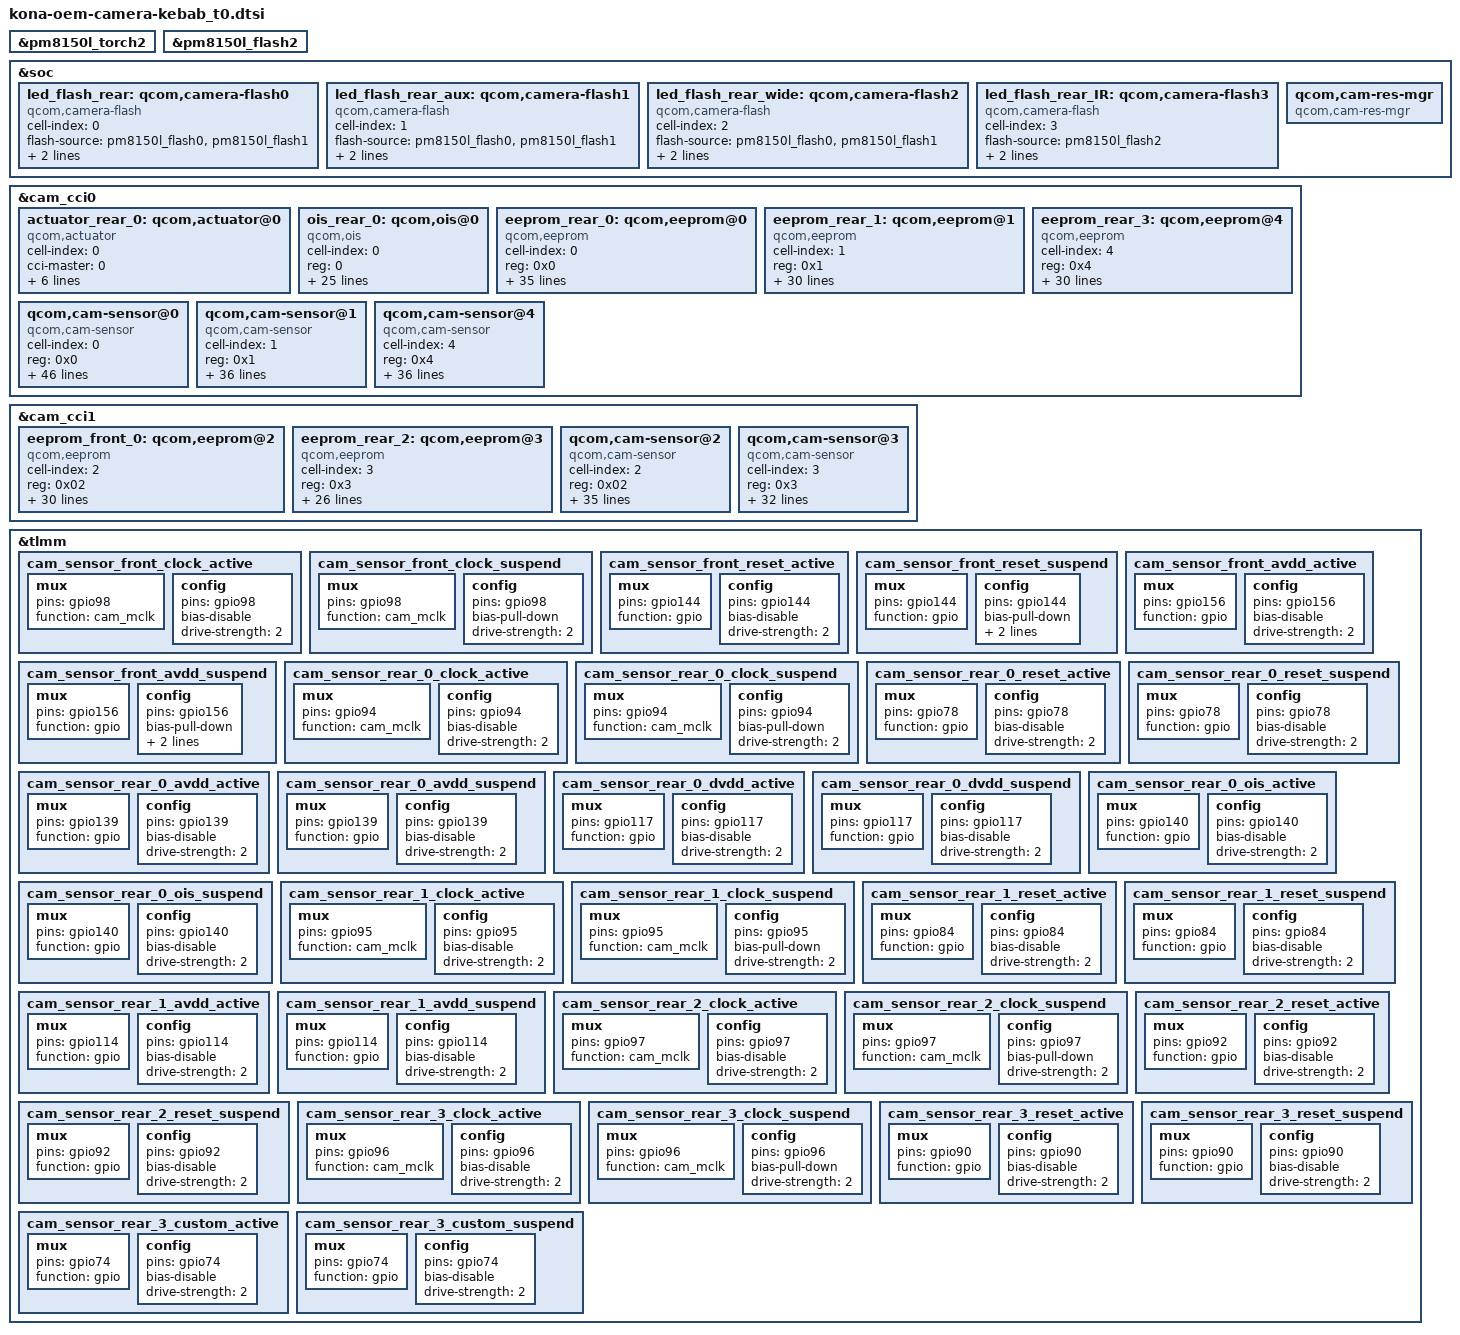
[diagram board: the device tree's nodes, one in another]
&pm8150l_torch2 {
	status = "ok";
};
&pm8150l_flash2 {
	status = "ok";
};

&soc {
    led_flash_rear: qcom,camera-flash0 {
        cell-index = <0>;
        compatible = "qcom,camera-flash";
        flash-source = <&pm8150l_flash0 &pm8150l_flash1>;
        torch-source = <&pm8150l_torch0 &pm8150l_torch1>;
        switch-source = <&pm8150l_switch2>;
        status = "ok";
    };

    led_flash_rear_aux: qcom,camera-flash1 {
        cell-index = <1>;
        compatible = "qcom,camera-flash";
        flash-source = <&pm8150l_flash0 &pm8150l_flash1>;
        torch-source = <&pm8150l_torch0 &pm8150l_torch1>;
        switch-source = <&pm8150l_switch2>;
        status = "ok";
    };

    led_flash_rear_wide: qcom,camera-flash2 {
        cell-index = <2>;
        compatible = "qcom,camera-flash";
        flash-source = <&pm8150l_flash0 &pm8150l_flash1>;
        torch-source = <&pm8150l_torch0 &pm8150l_torch1>;
        switch-source = <&pm8150l_switch2>;
        status = "ok";
    };

    led_flash_rear_IR: qcom,camera-flash3 {
        cell-index = <3>;
        compatible = "qcom,camera-flash";
        flash-source = <&pm8150l_flash2>;
        torch-source = <&pm8150l_torch2>;
        switch-source = <&pm8150l_switch3>;
        status = "ok";
    };

    qcom,cam-res-mgr {
        compatible = "qcom,cam-res-mgr";
        status = "ok";
    };
};

&cam_cci0 {
    actuator_rear_0: qcom,actuator@0 {
        cell-index = <0>;
        compatible = "qcom,actuator";
        cci-master = <0>;
        cam_vaf-supply = <&L3P>;
        regulator-names = "cam_vaf";
        rgltr-cntrl-support;
        rgltr-min-voltage = <2800000>;
        rgltr-max-voltage = <2800000>;
        rgltr-load-current = <600000>;
    };

    ois_rear_0: qcom,ois@0{
        cell-index = <0>;
        reg = <0>;
        compatible = "qcom,ois";
        cam_vio-supply = <&L4P>;              //pm8008_l4
        cam_vdig-supply = <&pm8150a_s8>;
        cam_vaf-supply = <&pm8150a_bob>;              //pm8008_l3
        regulator-names ="cam_vio","cam_vdig","cam_vaf";
        rgltr-cntrl-support;
        rgltr-min-voltage = <0 1350000 3000000>;
        rgltr-max-voltage = <0 1350000 3800000>;
        rgltr-load-current = <1000000 1000000 1000000>;
	    gpio-no-mux = <0>;
        pinctrl-names = "cam_default", "cam_suspend";
        pinctrl-0 = <&cam_sensor_rear_0_ois_active>;
        pinctrl-1 = <&cam_sensor_rear_0_ois_suspend>;
        gpios = <&tlmm 140 0>;
        gpio-vaf = <0>;
        gpio-req-tbl-num = <0>;
        gpio-req-tbl-flags = <0>;
        gpio-req-tbl-label = "CAMIF_vaf";
        cci-master = <0>;
        status = "ok";
        ois_gyro,position=<3>;
        ois,type=<0>;
        ois_gyro,type=<3>;
        ois,name="LC898124";
        ois_module,vendor=<0>;
        ois_actuator,vednor=<0>;
        ois,fw=<1>;
        download,fw=<1>;
    };

    /*EPROM wide camera: IMX586*/
    eeprom_rear_0: qcom,eeprom@0 {
        cell-index = <0>;
        compatible = "qcom,eeprom";
        reg = <0x0>;
        cam_vio-supply = <&L4P>;              //pm8008_l4
        cam_vdig-supply = <&pm8150a_s8>;
        cam_vana-supply = <&L7P>;             //pm8008_l7
        cam_v_custom1-supply = <&pm8150_s5>;
        cam_clk-supply = <&titan_top_gdsc>;
        regulator-names = "cam_vio","cam_vdig","cam_vana","cam_v_custom1",
            "cam_clk";
        rgltr-cntrl-support;
        rgltr-min-voltage = <0 1350000 2900000 2000000  0>;
        rgltr-max-voltage = <0 1350000 2900000 2000000  0>;
        rgltr-load-current = <1000000 1000000 300000 300000 0>;
        gpio-no-mux = <0>;
        pinctrl-names = "cam_default", "cam_suspend";
        pinctrl-0 = <&cam_sensor_rear_0_clock_active
                     &cam_sensor_rear_0_reset_active
                     &cam_sensor_rear_0_avdd_active
                     &cam_sensor_rear_0_dvdd_active>;
        pinctrl-1 = <&cam_sensor_rear_0_clock_suspend
                     &cam_sensor_rear_0_reset_suspend
                     &cam_sensor_rear_0_avdd_suspend
                     &cam_sensor_rear_0_dvdd_suspend>;
        gpios = <&tlmm 94 0>,
                <&tlmm 78 0>,
                <&tlmm 139 0>,
                <&tlmm 117 0>;
        use-shared-clk;
        gpio-reset = <1>;
        gpio-custom1 = <2>;
        gpio-vdig = <3>;
        gpio-req-tbl-num = <0 1 2 3>;
        gpio-req-tbl-flags = <1 0 0 0>;
        gpio-req-tbl-label = "CAM_MCLK0",
            "CAM_RESET0",
            "CAM_CUSTOM1",
            "CAM_VDIG";
        sensor-mode = <0>;
        cci-master = <0>;
        status = "ok";
        clocks = <&clock_camcc CAM_CC_MCLK0_CLK>;
        clock-names = "cam_clk";
        clock-cntl-level = "turbo";
        clock-rates = <19200000>;
    };

    /*EEPROM ultra_camera: IMX481 */
    eeprom_rear_1: qcom,eeprom@1 {
        cell-index = <1>;
        compatible = "qcom,eeprom";
        reg = <0x1>;
        cam_vio-supply = <&L4P>;
        cam_vana-supply = <&pm8150a_bob>;
        cam_vdig-supply = <&L1P>;
        cam_clk-supply = <&titan_top_gdsc>;
        regulator-names = "cam_vio","cam_vdig","cam_vana","cam_clk";
        rgltr-cntrl-support;
        rgltr-min-voltage = <0 1100000 3000000 0>;
        rgltr-max-voltage = <0 1100000 3800000 0>;
        rgltr-load-current = <1000000 1000000 300000 0>;
        gpio-no-mux = <0>;
        pinctrl-names = "cam_default", "cam_suspend";
        pinctrl-0 = <&cam_sensor_rear_1_clock_active
                     &cam_sensor_rear_1_reset_active
                     &cam_sensor_rear_1_avdd_active>;
        pinctrl-1 = <&cam_sensor_rear_1_clock_suspend
                     &cam_sensor_rear_1_reset_suspend
                     &cam_sensor_rear_1_avdd_suspend>;
        gpios = <&tlmm 95 0>,
                <&tlmm 84 0>,
                <&tlmm 114 0>;
        use-shared-clk;
        gpio-reset = <1>;
        gpio-vana = <2>;
        gpio-req-tbl-num = <0 1 2>;
        gpio-req-tbl-flags = <1 0 0>;
        gpio-req-tbl-label = "CAM_MCLK1",
            "CAM_RESET1",
            "CAM_VANA1";
        sensor-mode = <0>;
        cci-master = <1>;
        status = "ok";
        clocks = <&clock_camcc CAM_CC_MCLK1_CLK>;
        clock-names = "cam_clk";
        clock-cntl-level = "turbo";
        clock-rates = <19200000>;
    };

    /* EEPROM Macro Camera : GC02M1B */
    eeprom_rear_3: qcom,eeprom@4 {
        cell-index = <4>;
        compatible = "qcom,eeprom";
        reg = <0x4>;
        cam_vio-supply = <&L4P>;
        cam_vdig-supply = <&L4P>;
        cam_vana-supply = <&L5P>;
        cam_clk-supply = <&titan_top_gdsc>;
        regulator-names = "cam_vio","cam_vdig","cam_vana","cam_clk";
        rgltr-cntrl-support;
        rgltr-min-voltage = <0 1800000 2800000 0>;
        rgltr-max-voltage = <0 1800000 2800000 0>;
        rgltr-load-current = <0 300000 300000 0>;
        gpio-no-mux = <0>;
        pinctrl-names = "cam_default", "cam_suspend";
        pinctrl-0 = <&cam_sensor_rear_3_clock_active
                     &cam_sensor_rear_3_reset_active
                     &cam_sensor_rear_3_custom_active>;
        pinctrl-1 = <&cam_sensor_rear_3_clock_suspend
                     &cam_sensor_rear_3_reset_suspend
                     &cam_sensor_rear_3_custom_suspend>;
        gpios = <&tlmm 96 0>,
                <&tlmm 90 0>,
                <&tlmm 74 0>;
        use-shared-clk;
        gpio-reset = <1>;
        gpio-custom1 = <2>;
        gpio-req-tbl-num = <0 1 2>;
        gpio-req-tbl-flags = <1 0 0>;
        gpio-req-tbl-label = "CAM_MCLK4",
            "CAM_RESET4",
            "CAM_RESET_NEW";
        sensor-mode = <0>;
        cci-master = <1>;
        status = "ok";
        clocks = <&clock_camcc CAM_CC_MCLK2_CLK>;
        clock-names = "cam_clk";
        clock-cntl-level = "turbo";
        clock-rates = <19200000>;
    };

    /*wide camera: IMX586*/
    qcom,cam-sensor@0 {
        cell-index = <0>;
        compatible = "qcom,cam-sensor";
        reg = <0x0>;
        csiphy-sd-index = <0>;
        sensor-position-roll = <90>;
        sensor-position-pitch = <0>;
        sensor-position-yaw = <180>;
        actuator-src = <&actuator_rear_0>;
        eeprom-src = <&eeprom_rear_0>;
        ois-src = <&ois_rear_0>;
        led-flash-src = <&led_flash_rear>;
        cam_vio-supply = <&L4P>;              //pm8008_l4
        cam_vdig-supply = <&pm8150a_s8>;
        cam_vana-supply = <&L7P>;             //pm8008_l7
        cam_v_custom1-supply = <&pm8150_s5>;
        cam_vaf-supply = <&L3P>;              //pm8008_l3
        cam_clk-supply = <&titan_top_gdsc>;
        regulator-names = "cam_vio","cam_vdig","cam_vana","cam_v_custom1","cam_vaf",
            "cam_clk";
        rgltr-cntrl-support;
        rgltr-min-voltage = <0 1350000 2900000 2000000 2800000  0>;
        rgltr-max-voltage = <0 1350000 2900000 2000000 2800000  0>;
        rgltr-load-current = <1000000 1000000 300000 300000 1000000 0>;
        gpio-no-mux = <0>;
        pinctrl-names = "cam_default", "cam_suspend";
        pinctrl-0 = <&cam_sensor_rear_0_clock_active
                     &cam_sensor_rear_0_reset_active
                     &cam_sensor_rear_0_avdd_active
                     &cam_sensor_rear_0_dvdd_active>;
        pinctrl-1 = <&cam_sensor_rear_0_clock_suspend
                     &cam_sensor_rear_0_reset_suspend
                     &cam_sensor_rear_0_avdd_suspend
                     &cam_sensor_rear_0_dvdd_suspend>;
        gpios = <&tlmm 94 0>,
                <&tlmm 78 0>,
                <&tlmm 139 0>,
                <&tlmm 117 0>;
        use-shared-clk;
        gpio-reset = <1>;
        gpio-custom1 = <2>;
        gpio-vdig = <3>;
        gpio-req-tbl-num = <0 1 2 3>;
        gpio-req-tbl-flags = <1 0 0 0>;
        gpio-req-tbl-label = "CAM_MCLK0",
            "CAM_RESET0",
            "CAM_CUSTOM1",
            "CAM_VDIG";
        sensor-mode = <0>;
        cci-master = <0>;
        status = "ok";
        clocks = <&clock_camcc CAM_CC_MCLK0_CLK>;
        clock-names = "cam_clk";
        clock-cntl-level = "turbo";
        clock-rates = <19200000>;
    };

    /*ultra_camera: IMX481 */
    qcom,cam-sensor@1 {
        cell-index = <1>;
        compatible = "qcom,cam-sensor";
        reg = <0x1>;
        csiphy-sd-index = <1>;
        sensor-position-roll = <90>;
        sensor-position-pitch = <0>;
        sensor-position-yaw = <180>;
        eeprom-src = <&eeprom_rear_1>;
        led-flash-src = <&led_flash_rear_wide>;
        cam_vio-supply = <&L4P>;
        cam_vana-supply = <&pm8150a_bob>;
        cam_vdig-supply = <&L1P>;
        cam_clk-supply = <&titan_top_gdsc>;
        regulator-names = "cam_vio","cam_vdig","cam_vana","cam_clk";
        rgltr-cntrl-support;
        rgltr-min-voltage = <0 1100000 3300000 0>;
        rgltr-max-voltage = <0 1100000 3800000 0>;
        rgltr-load-current = <1000000 1000000 300000 0>;
        gpio-no-mux = <0>;
        pinctrl-names = "cam_default", "cam_suspend";
        pinctrl-0 = <&cam_sensor_rear_1_clock_active
                     &cam_sensor_rear_1_reset_active
                     &cam_sensor_rear_1_avdd_active>;
        pinctrl-1 = <&cam_sensor_rear_1_clock_suspend
                     &cam_sensor_rear_1_reset_suspend
                     &cam_sensor_rear_1_avdd_suspend>;
        gpios = <&tlmm 95 0>,
                <&tlmm 84 0>,
                <&tlmm 114 0>;
        use-shared-clk;
        gpio-reset = <1>;
        gpio-vana = <2>;
        gpio-req-tbl-num = <0 1 2>;
        gpio-req-tbl-flags = <1 0 0>;
        gpio-req-tbl-label = "CAM_MCLK1",
            "CAM_RESET1",
            "CAM_VANA1";
        sensor-mode = <0>;
        cci-master = <1>;
        status = "ok";
        clocks = <&clock_camcc CAM_CC_MCLK1_CLK>;
        clock-names = "cam_clk";
        clock-cntl-level = "turbo";
        clock-rates = <19200000>;
    };

    /* Macro Camera : GC02M1B */
    qcom,cam-sensor@4 {
        cell-index = <4>;
        compatible = "qcom,cam-sensor";
        reg = <0x4>;
        csiphy-sd-index = <2>;
        sensor-position-roll = <90>;
        sensor-position-pitch = <0>;
        sensor-position-yaw = <180>;
        eeprom-src = <&eeprom_rear_3>;
        led-flash-src = <&led_flash_rear_aux>;
        cam_vio-supply = <&L4P>;
        cam_vdig-supply = <&L4P>;
        cam_vana-supply = <&L5P>;
        cam_clk-supply = <&titan_top_gdsc>;
        regulator-names = "cam_vio","cam_vdig","cam_vana","cam_clk";
        rgltr-cntrl-support;
        rgltr-min-voltage = <0 1800000 2800000 0>;
        rgltr-max-voltage = <0 1800000 2800000 0>;
        rgltr-load-current = <0 300000 300000 0>;
        gpio-no-mux = <0>;
        pinctrl-names = "cam_default", "cam_suspend";
        pinctrl-0 = <&cam_sensor_rear_3_clock_active
                     &cam_sensor_rear_3_reset_active
                     &cam_sensor_rear_3_custom_active>;
        pinctrl-1 = <&cam_sensor_rear_3_clock_suspend
                     &cam_sensor_rear_3_reset_suspend
                     &cam_sensor_rear_3_custom_suspend>;
        gpios = <&tlmm 96 0>,
                <&tlmm 90 0>,
                <&tlmm 74 0>;
        use-shared-clk;
        gpio-reset = <1>;
        gpio-custom1 = <2>;
        gpio-req-tbl-num = <0 1 2>;
        gpio-req-tbl-flags = <1 0 0>;
        gpio-req-tbl-label = "CAM_MCLK4",
            "CAM_RESET4",
            "CAM_RESET_NEW";
        sensor-mode = <0>;
        cci-master = <1>;
        status = "ok";
        clocks = <&clock_camcc CAM_CC_MCLK2_CLK>;
        clock-names = "cam_clk";
        clock-cntl-level = "turbo";
        clock-rates = <19200000>;
    };

};

&cam_cci1 {

    /*EEPROM Front cam: IMX471 */
    eeprom_front_0: qcom,eeprom@2 {
        cell-index = <2>;
        compatible = "qcom,eeprom";
        reg = <0x02>;
        cam_vio-supply = <&L4P>;             //pm8008_l4
        cam_vdig-supply = <&L1P>;            //pm8008_l1
        cam_vana-supply = <&pm8150a_bob>;
        cam_clk-supply = <&titan_top_gdsc>;
        regulator-names = "cam_vio","cam_vdig","cam_vana",
            "cam_clk";
        rgltr-cntrl-support;
        rgltr-min-voltage = <0 1100000 3000000 0>;
        rgltr-max-voltage = <0 1100000 3800000 0>;
        rgltr-load-current = <1000000 1000000  300000 0>;
        gpio-no-mux = <0>;
        pinctrl-names = "cam_default", "cam_suspend";
        pinctrl-0 = <&cam_sensor_front_clock_active
                     &cam_sensor_front_reset_active
                     &cam_sensor_front_avdd_active>;
        pinctrl-1 = <&cam_sensor_front_clock_suspend
                     &cam_sensor_front_reset_suspend
                     &cam_sensor_front_avdd_suspend>;
        gpios = <&tlmm 98 0>,
                <&tlmm 144 0>,
                <&tlmm 156 0>;
        use-shared-clk;
        gpio-reset = <1>;
        gpio-vana = <2>;
        gpio-req-tbl-num = <0 1 2>;
        gpio-req-tbl-flags = <1 0 0>;
        gpio-req-tbl-label = "CAM_front_MCLK",
            "CAM_front_RESET",
            "CAM_front_VANA";
        sensor-mode = <0>;
        cci-master = <1>;
        status = "ok";
        clocks = <&clock_camcc CAM_CC_MCLK4_CLK>;
        clock-names = "cam_clk";
        clock-cntl-level = "turbo";
        clock-rates = <19200000>;
    };

    /*Micro: GC5035 */
    eeprom_rear_2: qcom,eeprom@3 {
        cell-index = <3>;
        compatible = "qcom,eeprom";
        reg = <0x3>;
        cam_vio-supply = <&L4P>;
        cam_vdig-supply = <&L2P>;
        cam_vana-supply = <&L6P>;
        cam_clk-supply = <&titan_top_gdsc>;
        regulator-names = "cam_vio","cam_vdig","cam_vana",
            "cam_clk";
        rgltr-cntrl-support;
        rgltr-min-voltage = <0 1200000 2800000 0>;
        rgltr-max-voltage = <0 1200000 2800000 0>;
        rgltr-load-current = <1000000 1000000 300000 0>;
        gpio-no-mux = <0>;
        pinctrl-names = "cam_default", "cam_suspend";
        pinctrl-0 = <&cam_sensor_rear_2_clock_active
                     &cam_sensor_rear_2_reset_active>;
        pinctrl-1 = <&cam_sensor_rear_2_clock_suspend
                     &cam_sensor_rear_2_reset_suspend>;
        gpios = <&tlmm 97 0>,
                <&tlmm 92 0>;
        use-shared-clk;
        gpio-reset = <1>;
        gpio-req-tbl-num = <0 1>;
        gpio-req-tbl-flags = <1 0>;
        gpio-req-tbl-label = "CAM_MCLK2",
            "CAM_RESET2";
        sensor-mode = <0>;
        cci-master = <0>;
        status = "ok";
        clocks = <&clock_camcc CAM_CC_MCLK3_CLK>;
        clock-names = "cam_clk";
        clock-cntl-level = "turbo";
        clock-rates = <19200000>;
    };

    /*Front cam: IMX471 */
    qcom,cam-sensor@2 {
        cell-index = <2>;
        compatible = "qcom,cam-sensor";
        reg = <0x02>;
        csiphy-sd-index = <4>;
        sensor-position-roll = <270>;
        sensor-position-pitch = <0>;
        sensor-position-yaw = <0>;
        eeprom-src = <&eeprom_front_0>;
        cam_vio-supply = <&L4P>;             //pm8008_l4
        cam_vdig-supply = <&L1P>;            //pm8008_l1
        cam_vana-supply = <&pm8150a_bob>;
        cam_clk-supply = <&titan_top_gdsc>;
        regulator-names = "cam_vio","cam_vdig","cam_vana",
            "cam_clk";
        rgltr-cntrl-support;
        rgltr-min-voltage = <0 1100000 3000000 0>;
        rgltr-max-voltage = <0 1100000 3800000 0>;
        rgltr-load-current = <1000000 1000000  300000 0>;
        gpio-no-mux = <0>;
        pinctrl-names = "cam_default", "cam_suspend";
        pinctrl-0 = <&cam_sensor_front_clock_active
                     &cam_sensor_front_reset_active
                     &cam_sensor_front_avdd_active>;
        pinctrl-1 = <&cam_sensor_front_clock_suspend
                     &cam_sensor_front_reset_suspend
                     &cam_sensor_front_avdd_suspend>;
        gpios = <&tlmm 98 0>,
                <&tlmm 144 0>,
                <&tlmm 156 0>;
        use-shared-clk;
        gpio-reset = <1>;
        gpio-vana = <2>;
        gpio-req-tbl-num = <0 1 2>;
        gpio-req-tbl-flags = <1 0 0>;
        gpio-req-tbl-label = "CAM_front_MCLK",
            "CAM_front_RESET",
            "CAM_front_VANA";
        sensor-mode = <0>;
        cci-master = <1>;
        status = "ok";
        clocks = <&clock_camcc CAM_CC_MCLK4_CLK>;
        clock-names = "cam_clk";
        clock-cntl-level = "turbo";
        clock-rates = <19200000>;
    };

    /*Micro: GC5035 */
    qcom,cam-sensor@3 {
        cell-index = <3>;
        compatible = "qcom,cam-sensor";
        reg = <0x3>;
        csiphy-sd-index = <3>;
        sensor-position-roll = <90>;
        sensor-position-pitch = <0>;
        sensor-position-yaw = <180>;
        eeprom-src = <&eeprom_rear_2>;
        led-flash-src = <&led_flash_rear_IR>;
        cam_vio-supply = <&L4P>;
        cam_vdig-supply = <&L2P>;
        cam_vana-supply = <&L6P>;
        cam_clk-supply = <&titan_top_gdsc>;
        regulator-names = "cam_vio","cam_vdig","cam_vana",
            "cam_clk";
        rgltr-cntrl-support;
        rgltr-min-voltage = <0 1200000 2800000 0>;
        rgltr-max-voltage = <0 1200000 2800000 0>;
        rgltr-load-current = <1000000 1000000 300000 0>;
        gpio-no-mux = <0>;
        pinctrl-names = "cam_default", "cam_suspend";
        pinctrl-0 = <&cam_sensor_rear_2_clock_active
                     &cam_sensor_rear_2_reset_active>;
        pinctrl-1 = <&cam_sensor_rear_2_clock_suspend
                     &cam_sensor_rear_2_reset_suspend>;
        gpios = <&tlmm 97 0>,
                <&tlmm 92 0>;
        use-shared-clk;
        gpio-reset = <1>;
        gpio-req-tbl-num = <0 1>;
        gpio-req-tbl-flags = <1 0>;
        gpio-req-tbl-label = "CAM_MCLK2",
            "CAM_RESET2";
        sensor-mode = <0>;
        cci-master = <0>;
        status = "ok";
        clocks = <&clock_camcc CAM_CC_MCLK3_CLK>;
        clock-names = "cam_clk";
        clock-cntl-level = "turbo";
        clock-rates = <19200000>;
    };

};

&tlmm {

    cam_sensor_front_clock_active: cam_sensor_front_clock_active {
        /* MCLK4 */
        mux {
            pins = "gpio98";
            function = "cam_mclk";
        };

        config {
            pins = "gpio98";
            bias-disable; /* No PULL */
            drive-strength = <2>; /* 2 MA */
        };
    };

    cam_sensor_front_clock_suspend: cam_sensor_front_clock_suspend {
        /* MCLK4 */
        mux {
            pins = "gpio98";
            function = "cam_mclk";
        };

        config {
            pins = "gpio98";
            bias-pull-down; /* PULL DOWN */
            drive-strength = <2>; /* 2 MA */
        };
    };

    cam_sensor_front_reset_active: cam_sensor_front_reset_active {
        /* RESET 4 */
        mux {
            pins = "gpio144";
            function = "gpio";
        };

        config {
            pins = "gpio144";
            bias-disable; /* No PULL */
            drive-strength = <2>; /* 2 MA */
        };
    };

    cam_sensor_front_reset_suspend: cam_sensor_front_reset_suspend {
        /* RESET 4 */
        mux {
            pins = "gpio144";
            function = "gpio";
        };

        config {
            pins = "gpio144";
            bias-pull-down; /* PULL DOWN */
            drive-strength = <2>; /* 2 MA */
            output-low;
        };
    };

    cam_sensor_front_avdd_active: cam_sensor_front_avdd_active {
        mux {
            pins = "gpio156";
            function = "gpio";
        };

        config {
            pins = "gpio156";
            bias-disable; /* No PULL */
            drive-strength = <2>; /* 2 MA */
        };
    };

    cam_sensor_front_avdd_suspend: cam_sensor_front_avdd_suspend {
        mux {
            pins = "gpio156";
            function = "gpio";
        };

        config {
            pins = "gpio156";
            bias-pull-down; /* PULL DOWN */
            drive-strength = <2>; /* 2 MA */
            output-low;
        };
    };

    cam_sensor_rear_0_clock_active: cam_sensor_rear_0_clock_active {
        /* MCLK0 */
        mux {
        pins = "gpio94";
            function = "cam_mclk";
        };

        config {
               pins = "gpio94";
               bias-disable; /* No PULL */
               drive-strength = <2>; /* 2 MA */
        };
    };

    cam_sensor_rear_0_clock_suspend: cam_sensor_rear_0_clock_suspend {
    /* MCLK0 */
    mux {
            pins = "gpio94";
            function = "cam_mclk";
        };

    config {
           pins = "gpio94";
           bias-pull-down; /* PULL DOWN */
               drive-strength = <2>; /* 2 MA */
    };
    };

    cam_sensor_rear_0_reset_active: cam_sensor_rear_0_reset_active {
        /* RESET, STANDBY */
        mux {
            pins = "gpio78";
            function = "gpio";
        };

        config {
            pins = "gpio78";
            bias-disable; /* No PULL */
            drive-strength = <2>; /* 2 MA */
        };
    };

    cam_sensor_rear_0_reset_suspend: cam_sensor_rear_0_reset_suspend {
        /* RESET, STANDBY */
        mux {
            pins = "gpio78";
            function = "gpio";
        };

        config {
            pins = "gpio78";
            bias-disable; /* No PULL */
            drive-strength = <2>; /* 2 MA */
        };
    };

    cam_sensor_rear_0_avdd_active: cam_sensor_rear_0_avdd_active {
        /* RESET, STANDBY */
        mux {
            pins = "gpio139";
            function = "gpio";
        };

        config {
            pins = "gpio139";
            bias-disable; /* No PULL */
            drive-strength = <2>; /* 2 MA */
        };
    };

    cam_sensor_rear_0_avdd_suspend: cam_sensor_rear_0_avdd_suspend {
        /* RESET, STANDBY */
        mux {
            pins = "gpio139";
            function = "gpio";
        };

        config {
            pins = "gpio139";
            bias-disable; /* No PULL */
            drive-strength = <2>; /* 2 MA */
        };
    };

    cam_sensor_rear_0_dvdd_active: cam_sensor_rear_0_dvdd_active {
        /* RESET, STANDBY */
        mux {
            pins = "gpio117";
            function = "gpio";
        };

        config {
            pins = "gpio117";
            bias-disable; /* No PULL */
            drive-strength = <2>; /* 2 MA */
        };
    };

    cam_sensor_rear_0_dvdd_suspend: cam_sensor_rear_0_dvdd_suspend {
        /* RESET, STANDBY */
        mux {
            pins = "gpio117";
            function = "gpio";
        };

        config {
            pins = "gpio117";
            bias-disable; /* No PULL */
            drive-strength = <2>; /* 2 MA */
        };
    };

    cam_sensor_rear_0_ois_active: cam_sensor_rear_0_ois_active {
        /* RESET, STANDBY */
        mux {
            pins = "gpio140";
            function = "gpio";
        };

        config {
            pins = "gpio140";
            bias-disable; /* No PULL */
            drive-strength = <2>; /* 2 MA */
        };
    };

    cam_sensor_rear_0_ois_suspend: cam_sensor_rear_0_ois_suspend {
        /* RESET, STANDBY */
        mux {
            pins = "gpio140";
            function = "gpio";
        };

        config {
            pins = "gpio140";
            bias-disable; /* No PULL */
            drive-strength = <2>; /* 2 MA */
        };
    };

    cam_sensor_rear_1_clock_active: cam_sensor_rear_1_clock_active {
        /* MCLK1 */
        mux {
            pins = "gpio95";
            function = "cam_mclk";
        };

        config {
               pins = "gpio95";
               bias-disable; /* No PULL */
               drive-strength = <2>; /* 2 MA */
        };
    };

    cam_sensor_rear_1_clock_suspend: cam_sensor_rear_1_clock_suspend {
        /* MCLK1 */
        mux {
            pins = "gpio95";
            function = "cam_mclk";
        };

        config {
               pins = "gpio95";
               bias-pull-down; /* PULL DOWN */
               drive-strength = <2>; /* 2 MA */
        };
   };

   cam_sensor_rear_1_reset_active: cam_sensor_rear_1_reset_active {
        /* RESET, STANDBY */
        mux {
            pins = "gpio84";
            function = "gpio";
        };

        config {
            pins = "gpio84";
            bias-disable; /* No PULL */
            drive-strength = <2>; /* 2 MA */
        };
    };

    cam_sensor_rear_1_reset_suspend: cam_sensor_rear_1_reset_suspend {
        /* RESET, STANDBY */
        mux {
            pins = "gpio84";
            function = "gpio";
        };

        config {
            pins = "gpio84";
            bias-disable; /* No PULL */
            drive-strength = <2>; /* 2 MA */
        };
    };

    cam_sensor_rear_1_avdd_active: cam_sensor_rear_1_avdd_active {
        /* RESET, STANDBY */
        mux {
            pins = "gpio114";
            function = "gpio";
        };

        config {
            pins = "gpio114";
            bias-disable; /* No PULL */
            drive-strength = <2>; /* 2 MA */
        };
    };

    cam_sensor_rear_1_avdd_suspend: cam_sensor_rear_1_avdd_suspend {
        /* RESET, STANDBY */
        mux {
            pins = "gpio114";
            function = "gpio";
        };

        config {
            pins = "gpio114";
            bias-disable; /* No PULL */
            drive-strength = <2>; /* 2 MA */
        };
    };

    cam_sensor_rear_2_clock_active: cam_sensor_rear_2_clock_active {
    /* MCLK3 */
        mux {
            pins = "gpio97";
            function = "cam_mclk";
        };

        config {
            pins = "gpio97";
            bias-disable; /* No PULL */
            drive-strength = <2>; /* 2 MA */
        };
    };

    cam_sensor_rear_2_clock_suspend: cam_sensor_rear_2_clock_suspend {
    /* MCLK3 */
        mux {
            pins = "gpio97";
            function = "cam_mclk";
        };

        config {
            pins = "gpio97";
            bias-pull-down; /* PULL DOWN */
            drive-strength = <2>; /* 2 MA */
        };
    };

    cam_sensor_rear_2_reset_active: cam_sensor_rear_2_reset_active {
        /* RESET, STANDBY */
        mux {
            pins = "gpio92";
            function = "gpio";
        };

        config {
            pins = "gpio92";
            bias-disable; /* No PULL */
            drive-strength = <2>; /* 2 MA */
        };
    };

    cam_sensor_rear_2_reset_suspend: cam_sensor_rear_2_reset_suspend {
        /* RESET, STANDBY */
        mux {
            pins = "gpio92";
            function = "gpio";
        };

        config {
            pins = "gpio92";
            bias-disable; /* No PULL */
            drive-strength = <2>; /* 2 MA */
        };
    };

    cam_sensor_rear_3_clock_active: cam_sensor_rear_3_clock_active {
        /* MCLK0 */
        mux {
        pins = "gpio96";
            function = "cam_mclk";
        };

        config {
               pins = "gpio96";
               bias-disable; /* No PULL */
               drive-strength = <2>; /* 2 MA */
        };
    };

    cam_sensor_rear_3_clock_suspend: cam_sensor_rear_3_clock_suspend {
    /* MCLK0 */
    mux {
            pins = "gpio96";
            function = "cam_mclk";
        };

    config {
           pins = "gpio96";
           bias-pull-down; /* PULL DOWN */
               drive-strength = <2>; /* 2 MA */
    };
    };

    cam_sensor_rear_3_reset_active: cam_sensor_rear_3_reset_active {
        /* RESET, STANDBY */
        mux {
            pins = "gpio90";
            function = "gpio";
        };

        config {
            pins = "gpio90";
            bias-disable; /* No PULL */
            drive-strength = <2>; /* 2 MA */
        };
    };

    cam_sensor_rear_3_reset_suspend: cam_sensor_rear_3_reset_suspend {
        /* RESET, STANDBY */
        mux {
            pins = "gpio90";
            function = "gpio";
        };

        config {
            pins = "gpio90";
            bias-disable; /* No PULL */
            drive-strength = <2>; /* 2 MA */
        };
    };

    cam_sensor_rear_3_custom_active: cam_sensor_rear_3_custom_active {
        /* RESET, STANDBY */
        mux {
            pins = "gpio74";
            function = "gpio";
        };

        config {
            pins = "gpio74";
            bias-disable; /* No PULL */
            drive-strength = <2>; /* 2 MA */
        };
    };

    cam_sensor_rear_3_custom_suspend: cam_sensor_rear_3_custom_suspend {
        /* RESET, STANDBY */
        mux {
            pins = "gpio74";
            function = "gpio";
        };

        config {
            pins = "gpio74";
            bias-disable; /* No PULL */
            drive-strength = <2>; /* 2 MA */
        };
    };
};
